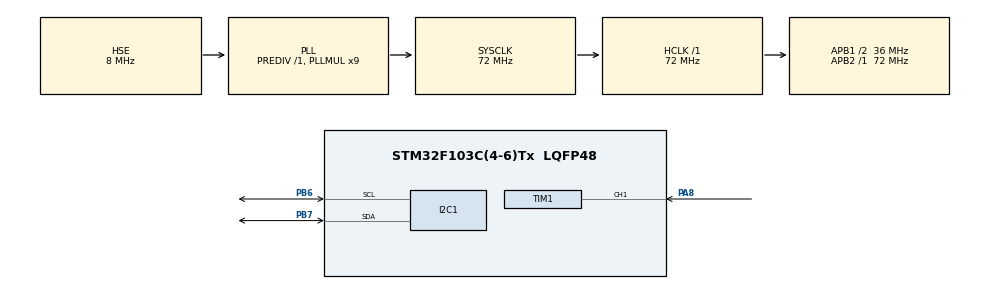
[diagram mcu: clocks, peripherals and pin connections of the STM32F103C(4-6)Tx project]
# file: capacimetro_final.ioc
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Mcu.Family=STM32F1
RCC.PLLSourceVirtual=RCC_PLLSOURCE_HSE
PD1-OSC_OUT.Mode=HSE-External-Oscillator
PD0-OSC_IN.Signal=RCC_OSC_IN
RCC.APB1CLKDivider=RCC_HCLK_DIV2
RCC.SYSCLKSource=RCC_SYSCLKSOURCE_PLLCLK
ProjectManager.StackSize=0x400
PD1-OSC_OUT.Signal=RCC_OSC_OUT
PA13.Signal=SYS_JTMS-SWDIO
TIM1.Prescaler=63
SH.S_TIM1_CH1.0=TIM1_CH1,Input_Capture1_from_TI1
SH.S_TIM1_CH1.1=TIM1_CH1,Input_Capture2_from_TI1
ProjectManager.TargetToolchain=STM32CubeIDE
RCC.HCLKFreq_Value=72000000
RCC.APB2TimFreq_Value=72000000
PB6.Signal=I2C1_SCL
PB6.Mode=I2C
RCC.USBFreq_Value=72000000
RCC.AHBFreq_Value=72000000
PD0-OSC_IN.Mode=HSE-External-Oscillator
board=custom
RCC.PLLMUL=RCC_PLL_MUL9
RCC.APB2Freq_Value=72000000
PA14.Mode=Serial_Wire
PB7.Signal=I2C1_SDA
PA8.Signal=S_TIM1_CH1
PA13.Mode=Serial_Wire
TIM1.Channel-Input_Capture2_from_TI1=TIM_CHANNEL_2
Mcu.Name=STM32F103C(4-6)Tx
VP_TIM1_VS_ClockSourceINT.Mode=Internal
NVIC.TIM1_CC_IRQn=true\:0\:0\:false\:false\:true\:true\:true
RCC.SYSCLKFreq_VALUE=72000000
Mcu.Package=LQFP48
TIM1.Channel-Input_Capture1_from_TI1=TIM_CHANNEL_1
PB7.Mode=I2C
PA14.Signal=SYS_JTCK-SWCLK
ProjectManager.HeapSize=0x200
NVIC.PriorityGroup=NVIC_PRIORITYGROUP_4
TIM1.ICPolarity_CH2=TIM_INPUTCHANNELPOLARITY_FALLING
RCC.APB1TimFreq_Value=72000000
RCC.APB1Freq_Value=36000000

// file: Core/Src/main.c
/* USER CODE BEGIN Header */
/**
  ******************************************************************************
  * @file           : main.c
  * @brief          : Main program body
  ******************************************************************************
  * @attention
  *
  * <h2><center>&copy; Copyright (c) 2021 STMicroelectronics.
  * All rights reserved.</center></h2>
  *
  * This software component is licensed by ST under BSD 3-Clause license,
  * the "License"; You may not use this file except in compliance with the
  * License. You may obtain a copy of the License at:
  *                        opensource.org/licenses/BSD-3-Clause
  *
  ******************************************************************************
  */
/* USER CODE END Header */
#include "main.h"

/* USER CODE BEGIN Includes */

#include <math.h>
#include "i2c-lcd.h"

/* USER CODE END Includes */

I2C_HandleTypeDef hi2c1;

TIM_HandleTypeDef htim1;

void SystemClock_Config(void);
static void MX_GPIO_Init(void);
static void MX_I2C1_Init(void);
static void MX_TIM1_Init(void);

/* USER CODE BEGIN 0 */
int contador=0;

int soma=0;

int frequencia;

float cap;

float media;

int RA=10000;

int RB=100000;

/* USER CODE END 0 */

int main(void)
{
  /* USER CODE BEGIN 1 */
	//HAL_TIM_Base_Start(&htim1);

  /* USER CODE END 1 */

  /* MCU Configuration--------------------------------------------------------*/

  /* Reset of all peripherals, Initializes the Flash interface and the Systick. */
  HAL_Init();

  /* Configure the system clock */
  SystemClock_Config();

  /* Initialize all configured peripherals */

  MX_GPIO_Init();
  MX_I2C1_Init();
  MX_TIM1_Init();

  /* USER CODE BEGIN 2 */

HAL_TIM_IC_Start_IT(&htim1, TIM_CHANNEL_1);
HAL_TIM_IC_Start_IT(&htim1, TIM_CHANNEL_2);

  lcd_init (); // inicializa o LCD

  lcd_put_cur(0, 0); // posiciona o cursor do LCD na linha e coluna 0

  lcd_send_string ("MICROS"); // escreve o texto na posição selecionada

  HAL_Delay(1000); // atraso de 1s

  lcd_put_cur(1, 0); // posiciona o cursor do LCD na linha 1 e coluna 0

  lcd_send_string("2020.2");// escreve o texto na posição selecionada

  HAL_Delay(3000);// atraso de 3s

  lcd_clear (); // limpa o LCD

  HAL_Delay(3000);// atraso de 3s

  /* USER CODE END 2 */

  /* Infinite loop */
  while (1)
  {

    /* USER CODE BEGIN 3 */
	  while(contador<1000)

	   {
		  void TIM1_CC_IRQHandler(void);
	  /* Rotina para amostragem dos valores de freqüência */
	  }

	  media = soma/1000.0;

	  frequencia = 72000000.0 / media;

	  cap=1.0E9*(1.44/((RA+2*RB)*frequencia));

	  lcd_put_cur(0, 0);

	  lcd_send_string ("FREQUENCIA:");

	  HAL_Delay(1000);

	  lcd_put_cur(1, 0);

	  lcd_send_data (frequencia);

	  lcd_send_string ("Hz");

	  HAL_Delay(5000);

      lcd_clear ();

      HAL_Delay(3000);

      lcd_send_string ("CAPACITANCIA:");

      	  HAL_Delay(1000);

      	  lcd_put_cur(1, 0);

      	  lcd_send_data (cap);
      	  lcd_send_string ("nF");

	  soma=0;
	  contador=0;
  }
  /* USER CODE END 3 */
}

void SystemClock_Config(void)
{
  RCC_OscInitTypeDef RCC_OscInitStruct = {0};
  RCC_ClkInitTypeDef RCC_ClkInitStruct = {0};

  /** Initializes the RCC Oscillators according to the specified parameters
  * in the RCC_OscInitTypeDef structure.
  */
  RCC_OscInitStruct.OscillatorType = RCC_OSCILLATORTYPE_HSE;
  RCC_OscInitStruct.HSEState = RCC_HSE_ON;
  RCC_OscInitStruct.HSEPredivValue = RCC_HSE_PREDIV_DIV1;
  RCC_OscInitStruct.HSIState = RCC_HSI_ON;
  RCC_OscInitStruct.PLL.PLLState = RCC_PLL_ON;
  RCC_OscInitStruct.PLL.PLLSource = RCC_PLLSOURCE_HSE;
  RCC_OscInitStruct.PLL.PLLMUL = RCC_PLL_MUL9;
  if (HAL_RCC_OscConfig(&RCC_OscInitStruct) != HAL_OK)
  {
    Error_Handler();
  }
  /** Initializes the CPU, AHB and APB buses clocks
  */
  RCC_ClkInitStruct.ClockType = RCC_CLOCKTYPE_HCLK|RCC_CLOCKTYPE_SYSCLK
                              |RCC_CLOCKTYPE_PCLK1|RCC_CLOCKTYPE_PCLK2;
  RCC_ClkInitStruct.SYSCLKSource = RCC_SYSCLKSOURCE_PLLCLK;
  RCC_ClkInitStruct.AHBCLKDivider = RCC_SYSCLK_DIV1;
  RCC_ClkInitStruct.APB1CLKDivider = RCC_HCLK_DIV2;
  RCC_ClkInitStruct.APB2CLKDivider = RCC_HCLK_DIV1;

  if (HAL_RCC_ClockConfig(&RCC_ClkInitStruct, FLASH_LATENCY_2) != HAL_OK)
  {
    Error_Handler();
  }
}

static void MX_I2C1_Init(void)
{

  hi2c1.Instance = I2C1;
  hi2c1.Init.ClockSpeed = 100000;
  hi2c1.Init.DutyCycle = I2C_DUTYCYCLE_2;
  hi2c1.Init.OwnAddress1 = 0;
  hi2c1.Init.AddressingMode = I2C_ADDRESSINGMODE_7BIT;
  hi2c1.Init.DualAddressMode = I2C_DUALADDRESS_DISABLE;
  hi2c1.Init.OwnAddress2 = 0;
  hi2c1.Init.GeneralCallMode = I2C_GENERALCALL_DISABLE;
  hi2c1.Init.NoStretchMode = I2C_NOSTRETCH_DISABLE;
  if (HAL_I2C_Init(&hi2c1) != HAL_OK)
  {
    Error_Handler();
  }

}

static void MX_TIM1_Init(void)
{

  TIM_ClockConfigTypeDef sClockSourceConfig = {0};
  TIM_MasterConfigTypeDef sMasterConfig = {0};
  TIM_IC_InitTypeDef sConfigIC = {0};

  htim1.Instance = TIM1;
  htim1.Init.Prescaler = 63;
  htim1.Init.CounterMode = TIM_COUNTERMODE_UP;
  htim1.Init.Period = 65535;
  htim1.Init.ClockDivision = TIM_CLOCKDIVISION_DIV1;
  htim1.Init.RepetitionCounter = 0;
  htim1.Init.AutoReloadPreload = TIM_AUTORELOAD_PRELOAD_DISABLE;
  if (HAL_TIM_Base_Init(&htim1) != HAL_OK)
  {
    Error_Handler();
  }
  sClockSourceConfig.ClockSource = TIM_CLOCKSOURCE_INTERNAL;
  if (HAL_TIM_ConfigClockSource(&htim1, &sClockSourceConfig) != HAL_OK)
  {
    Error_Handler();
  }
  if (HAL_TIM_IC_Init(&htim1) != HAL_OK)
  {
    Error_Handler();
  }
  sMasterConfig.MasterOutputTrigger = TIM_TRGO_RESET;
  sMasterConfig.MasterSlaveMode = TIM_MASTERSLAVEMODE_DISABLE;
  if (HAL_TIMEx_MasterConfigSynchronization(&htim1, &sMasterConfig) != HAL_OK)
  {
    Error_Handler();
  }
  sConfigIC.ICPolarity = TIM_INPUTCHANNELPOLARITY_RISING;
  sConfigIC.ICSelection = TIM_ICSELECTION_DIRECTTI;
  sConfigIC.ICPrescaler = TIM_ICPSC_DIV1;
  sConfigIC.ICFilter = 0;
  if (HAL_TIM_IC_ConfigChannel(&htim1, &sConfigIC, TIM_CHANNEL_1) != HAL_OK)
  {
    Error_Handler();
  }
  sConfigIC.ICPolarity = TIM_INPUTCHANNELPOLARITY_FALLING;
  sConfigIC.ICSelection = TIM_ICSELECTION_INDIRECTTI;
  if (HAL_TIM_IC_ConfigChannel(&htim1, &sConfigIC, TIM_CHANNEL_2) != HAL_OK)
  {
    Error_Handler();
  }

}

static void MX_GPIO_Init(void)
{

  /* GPIO Ports Clock Enable */
  __HAL_RCC_GPIOD_CLK_ENABLE();
  __HAL_RCC_GPIOA_CLK_ENABLE();
  __HAL_RCC_GPIOB_CLK_ENABLE();

}

void Error_Handler(void)
{
  __disable_irq();
  while (1)
  {
  }
}

/************************ (C) COPYRIGHT STMicroelectronics *****END OF FILE****/
